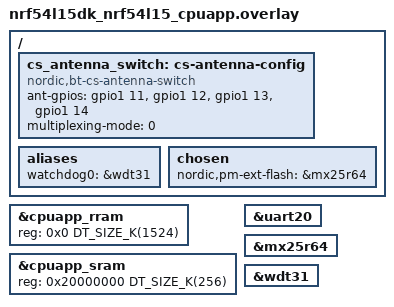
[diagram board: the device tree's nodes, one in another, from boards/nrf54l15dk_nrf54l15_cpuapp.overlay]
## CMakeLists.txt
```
#
# Copyright (c) 2021 Nordic Semiconductor ASA
#
# SPDX-License-Identifier: LicenseRef-Nordic-5-Clause
#

cmake_minimum_required(VERSION 3.20.0)

find_package(Zephyr HINTS $ENV{ZEPHYR_BASE})

project(matter-occupancy-sensor)

# Enable GNU STD support.
include(${ZEPHYR_CONNECTEDHOMEIP_MODULE_DIR}/config/nrfconnect/app/enable-gnu-std.cmake)

# NORDIC SDK APP START

# Include all source files that are located in the Matter common directory.
include(${ZEPHYR_NRF_MODULE_DIR}/samples/matter/common/cmake/source_common.cmake)

# Include Data Model utils
include(${ZEPHYR_NRF_MODULE_DIR}/samples/matter/common/cmake/data_model.cmake)

include(${ZEPHYR_NRF_MODULE_DIR}/samples/matter/common/cmake/zap_helpers.cmake)
ncs_get_zap_parent_dir(ZAP_PARENT_DIR)

target_include_directories(app PRIVATE
    src
    ${ZAP_PARENT_DIR}
)

target_sources(app PRIVATE
    src/app_task.cpp
    src/main.cpp
    src/zcl_callbacks.cpp
    src/occupancy_sensor_base.cpp
    src/occupancy_sensor_pir.cpp
    src/occupancy_sensor_rfs.cpp
    src/channel_sounding_ras_initiator.c
)

target_sources_ifdef(CONFIG_PIR_SUPPORT
	app
	PRIVATE
	src/occupancy_sensor_pir.cpp
)

ncs_configure_data_model()
# NORDIC SDK APP END
```

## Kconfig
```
#
# Copyright (c) 2022 Nordic Semiconductor
#
# SPDX-License-Identifier: LicenseRef-Nordic-5-Clause
#
mainmenu "Matter nRF Connect Occupancy Sensor Example Application"

config PIR_SUPPORT
	bool "PIR sensor support"
	help
	  Enable this option to include Passive Infrared (PIR) sensor support
	  for occupancy detection.

config SIMULATED_PIR_SENSOR
	bool "Simulated PIR sensor with button"
	depends on PIR_SUPPORT
	help
	  Enable this option to simulate PIR sensor input using a button.

config HOLD_TIME_LIMIT_MIN_SEC
	int "Occupancy sensor hold time limit (min)"
	default 1
	range 1 600
	help
	  Minimum time in seconds that the occupancy state remains "occupied"
	  after motion is detected.

config HOLD_TIME_LIMIT_MAX_SEC
	int "Occupancy sensor hold time limit (max)"
	default 600
	range 1 600
	help
	  Maximum time in seconds that the occupancy state remains "occupied"
	  after motion is detected.

config HOLD_TIME_LIMIT_DEFAULT_SEC
	int "Occupancy sensor hold time limit (default)"
	default 10
	range HOLD_TIME_LIMIT_MIN_SEC HOLD_TIME_LIMIT_MAX_SEC
	help
	  Default time in seconds that the occupancy state remains "occupied"
	  after motion is detected.

config HOLD_TIME_LIMIT_RFS_SEC
	int "RF Sensing occupancy hold time limit"
	default 30
	range HOLD_TIME_LIMIT_MIN_SEC HOLD_TIME_LIMIT_MAX_SEC
	help
	  Default time in seconds that the occupancy state remains "occupied"
	  after motion is detected using RF Sensing.

config HOLD_TIME_LIMIT_PIR_SEC
	int "PIR sensor occupancy hold time limit"
	default 10
	range HOLD_TIME_LIMIT_MIN_SEC HOLD_TIME_LIMIT_MAX_SEC
	help
	  Default time in seconds that the occupancy state remains "occupied"
	  after motion is detected using PIR sensor.

config RFS_ACTIVATED_BY_PIR
	bool "RF Sensing activated by PIR sensor"
	depends on PIR_SUPPORT
	help
	  Enable this option to activate RF Sensing only when the PIR sensor
	  detects motion.

config RFS_SENSING_ACTIVE_INTERVAL_MS
	int "RF Sensing active interval"
	default 4000
	range 1000 60000
	help
	  Time interval (in milliseconds) for which RF Sensing remains active
	  before going to sleep (if RFS_ACTIVATED_BY_PIR is enabled, this
	  interval starts after PIR sensor detects motion).

config RFS_SENSING_NORMAL_INACTIVE_INTERVAL_MS
	int "RF Sensing inactive interval in normal mode"
	default 3000
	range 1000 60000
	help
	  Time interval (in milliseconds) in normal mode for which RF Sensing
	  remains inactive.

config RFS_SENSING_LOW_POWER_INACTIVE_INTERVAL_MS
	int "RF Sensing inactive interval in low power mode"
	default 30000
	range 1000 60000
	help
	  Time interval (in milliseconds) in low power mode for which RF Sensing
	  remains inactive.

config RFS_FILTER_RSSI_THRESHOLD
	int "RF Sensing filter RSSI threshold"
	default -80
	range -127 -70
	help
	  RSSI threshold (in dBm) for filtering out weak RF signals.

config RFS_OCCUPANCY_THRESHOLD
	int "RF Sensing occupancy threshold"
	default 5
	range 2 10
	help
	  Range of valid RF signals required to determine occupancy in meter.

# Sample configuration used for Thread networking
if OPENTHREAD

choice OPENTHREAD_NORDIC_LIBRARY_CONFIGURATION
	default OPENTHREAD_NORDIC_LIBRARY_MTD
endchoice

choice OPENTHREAD_DEVICE_TYPE
	default OPENTHREAD_MTD
endchoice

config CHIP_ENABLE_ICD_SUPPORT
	default y

# Reduce Thread TX output power to 0 dBm for SED device
config OPENTHREAD_DEFAULT_TX_POWER
	int
	default 0

endif # OPENTHREAD

source "${ZEPHYR_CONNECTEDHOMEIP_MODULE_DIR}/config/nrfconnect/chip-module/Kconfig.features"
source "${ZEPHYR_CONNECTEDHOMEIP_MODULE_DIR}/config/nrfconnect/chip-module/Kconfig.defaults"
source "${ZEPHYR_NRF_MODULE_DIR}/samples/matter/common/src/Kconfig"
source "Kconfig.zephyr"
```

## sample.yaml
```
sample:
  description: Matter Occupancy Sensor sample
  name: Matter Occupancy Sensor
common:
  tags:
    - sysbuild
    - ci_samples_matter
tests:
  sample.matter.occupancy_sensor.debug:
    sysbuild: true
    build_only: true
    extra_args:
      - CONFIG_NCS_SAMPLE_MATTER_OPERATIONAL_KEYS_MIGRATION_TO_ITS=y
    integration_platforms:
      - nrf52840dk/nrf52840
      - nrf5340dk/nrf5340/cpuapp
      - nrf7002dk/nrf5340/cpuapp
      - nrf54l15dk/nrf54l15/cpuapp
      - nrf54l15dk/nrf54l15/cpuapp/ns
      - nrf54l15dk/nrf54l10/cpuapp
      - nrf54lm20dk/nrf54lm20a/cpuapp
    platform_allow:
      - nrf52840dk/nrf52840
      - nrf5340dk/nrf5340/cpuapp
      - nrf7002dk/nrf5340/cpuapp
      - nrf54l15dk/nrf54l15/cpuapp
      - nrf54l15dk/nrf54l15/cpuapp/ns
      - nrf54l15dk/nrf54l10/cpuapp
      - nrf54lm20dk/nrf54lm20a/cpuapp
  sample.matter.occupancy_sensor.release:
    sysbuild: true
    build_only: true
    extra_args:
      - FILE_SUFFIX=release
      - CONFIG_NCS_SAMPLE_MATTER_OPERATIONAL_KEYS_MIGRATION_TO_ITS=y
    integration_platforms:
      - nrf52840dk/nrf52840
      - nrf5340dk/nrf5340/cpuapp
      - nrf7002dk/nrf5340/cpuapp
      - nrf54l15dk/nrf54l15/cpuapp
      - nrf54l15dk/nrf54l15/cpuapp/ns
      - nrf54l15dk/nrf54l10/cpuapp
      - nrf54lm20dk/nrf54lm20a/cpuapp
    platform_allow:
      - nrf52840dk/nrf52840
      - nrf5340dk/nrf5340/cpuapp
      - nrf7002dk/nrf5340/cpuapp
      - nrf54l15dk/nrf54l15/cpuapp
      - nrf54l15dk/nrf54l15/cpuapp/ns
      - nrf54l15dk/nrf54l10/cpuapp
      - nrf54lm20dk/nrf54lm20a/cpuapp
  sample.matter.occupancy_sensor.smp_dfu:
    sysbuild: true
    build_only: true
    extra_args:
      - CONFIG_CHIP_DFU_OVER_BT_SMP=y
      - CONFIG_NCS_SAMPLE_MATTER_OPERATIONAL_KEYS_MIGRATION_TO_ITS=y
    integration_platforms:
      - nrf52840dk/nrf52840
      - nrf5340dk/nrf5340/cpuapp
      - nrf7002dk/nrf5340/cpuapp
      - nrf54l15dk/nrf54l15/cpuapp
      - nrf54l15dk/nrf54l15/cpuapp/ns
      - nrf54l15dk/nrf54l10/cpuapp
      - nrf54lm20dk/nrf54lm20a/cpuapp
    platform_allow:
      - nrf52840dk/nrf52840
      - nrf5340dk/nrf5340/cpuapp
      - nrf7002dk/nrf5340/cpuapp
      - nrf54l15dk/nrf54l15/cpuapp
      - nrf54l15dk/nrf54l15/cpuapp/ns
      - nrf54l15dk/nrf54l10/cpuapp
      - nrf54lm20dk/nrf54lm20a/cpuapp
  sample.matter.occupancy_sensor.release.internal:
    sysbuild: true
    build_only: true
    extra_args:
      - FILE_SUFFIX=internal
      - occupancy_sensor_EXTRA_CONF_FILE=prj_release.conf
    integration_platforms:
      - nrf54l15dk/nrf54l15/cpuapp
      - nrf54lm20dk/nrf54lm20a/cpuapp
    platform_allow:
      - nrf54l15dk/nrf54l15/cpuapp
      - nrf54lm20dk/nrf54lm20a/cpuapp
  sample.matter.occupancy_sensor.release.internal.smp_dfu:
    sysbuild: true
    build_only: true
    extra_args:
      - FILE_SUFFIX=internal
      - CONFIG_CHIP_DFU_OVER_BT_SMP=y
      - occupancy_sensor_EXTRA_CONF_FILE=prj_release.conf
    integration_platforms:
      - nrf54l15dk/nrf54l15/cpuapp
      - nrf54lm20dk/nrf54lm20a/cpuapp
    platform_allow:
      - nrf54l15dk/nrf54l15/cpuapp
      - nrf54lm20dk/nrf54lm20a/cpuapp
  sample.matter.occupancy_sensor.cc3xx_backend:
    sysbuild: true
    build_only: true
    extra_args:
      - CONFIG_PSA_CRYPTO_DRIVER_CC3XX=y
    integration_platforms:
      - nrf52840dk/nrf52840
      - nrf5340dk/nrf5340/cpuapp
    platform_allow:
      - nrf52840dk/nrf52840
      - nrf5340dk/nrf5340/cpuapp
  sample.matter.occupancy_sensor.smp_dfu.old_ec:
    sysbuild: true
    build_only: true
    extra_args:
      - CONFIG_CHIP_DFU_OVER_BT_SMP=y
      - SB_CONFIG_BOOT_SIGNATURE_TYPE_RSA=y
      - CONFIG_SETTINGS_ZMS_LEGACY=y
    integration_platforms:
      - nrf54l15dk/nrf54l15/cpuapp
    platform_allow:
      - nrf54l15dk/nrf54l15/cpuapp
  sample.matter.occupancy_sensor.certification:
    sysbuild: true
    build_only: true
    extra_args:
      - CONFIG_NCS_SAMPLE_MATTER_CERTIFICATION=y
      - OVERLAY_CONFIG="../common/src/certification/thread_platform/overlay-thread_platform.conf"
      - occupancy_sensor_SNIPPET="diagnostic-logs;matter-debug"
    integration_platforms:
      - nrf52840dk/nrf52840
      - nrf5340dk/nrf5340/cpuapp
      - nrf54l15dk/nrf54l15/cpuapp
      - nrf54lm20dk/nrf54lm20a/cpuapp
    platform_allow:
      - nrf52840dk/nrf52840
      - nrf5340dk/nrf5340/cpuapp
      - nrf54l15dk/nrf54l15/cpuapp
      - nrf54lm20dk/nrf54lm20a/cpuapp
```

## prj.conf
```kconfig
#
# Copyright (c) 2021 Nordic Semiconductor ASA
#
# SPDX-License-Identifier: LicenseRef-Nordic-5-Clause
#

# This sample uses Kconfig.defaults to set options common for all
# samples. This file should contain only options specific for this sample
# or overrides of default values.

# Enable CHIP
CONFIG_CHIP=y
CONFIG_CHIP_PROJECT_CONFIG="src/chip_project_config.h"

# Configure ZAP file name
CONFIG_NCS_SAMPLE_MATTER_ZAP_FILE_PATH="${APPLICATION_CONFIG_DIR}/src/default_zap/occupancy_sensor.zap"

# 32768 == 0x8000 (example Product ID added temporaly,
# but it must be changed with proper PID from the list:
# https://github.com/project-chip/connectedhomeip/blob/482e6fd03196a6de45465a90003947ef4b86e0b1/docs/examples/discussion/PID_allocation_for_example_apps.md)
CONFIG_CHIP_DEVICE_PRODUCT_ID=32768
CONFIG_STD_CPP17=y

# Disable Matter pairing automatically on application start.
CONFIG_CHIP_ENABLE_PAIRING_AUTOSTART=n

# Enable Matter extended announcement and increase duration to 1 hour.
CONFIG_CHIP_BLE_EXT_ADVERTISING=y
CONFIG_CHIP_BLE_ADVERTISING_DURATION=60

# Add support for LEDs and buttons on Nordic development kits
CONFIG_DK_LIBRARY=y

# Bluetooth Low Energy configuration
CONFIG_BT_DEVICE_NAME="M-Occupancy"

# Other settings
CONFIG_THREAD_NAME=y
CONFIG_MPU_STACK_GUARD=y
CONFIG_RESET_ON_FATAL_ERROR=n
CONFIG_CHIP_LIB_SHELL=y
CONFIG_NCS_SAMPLE_MATTER_TEST_SHELL=y

# Disable NFC onboarding
CONFIG_CHIP_NFC_ONBOARDING_PAYLOAD=n

# Reduce application size
CONFIG_USE_SEGGER_RTT=n

# Enable Factory Data feature
CONFIG_CHIP_FACTORY_DATA=y
CONFIG_CHIP_FACTORY_DATA_BUILD=y

CONFIG_NCS_SAMPLES_DEFAULTS=y

CONFIG_BT=y
CONFIG_BT_SMP=y
CONFIG_BT_CENTRAL=y
CONFIG_BT_MAX_CONN=1
CONFIG_BT_BONDABLE=y
CONFIG_BT_SETTINGS=y
CONFIG_BT_ID_MAX=2
CONFIG_BT_MAX_PAIRED=2

CONFIG_BT_GATT_CLIENT=y
CONFIG_BT_GATT_DYNAMIC_DB=y

CONFIG_BT_CHANNEL_SOUNDING=y
CONFIG_BT_RAS=y
CONFIG_BT_RAS_RREQ=y

CONFIG_BT_SCAN=y
CONFIG_BT_SCAN_FILTER_ENABLE=y
CONFIG_BT_SCAN_UUID_CNT=1
CONFIG_BT_SCAN_ADDRESS_CNT=2

# The Ranging Profile recommends a MTU of at least 247 octets.
CONFIG_BT_L2CAP_TX_MTU=498
CONFIG_BT_BUF_ACL_TX_SIZE=502
CONFIG_BT_BUF_ACL_RX_SIZE=502
CONFIG_BT_ATT_PREPARE_COUNT=3
CONFIG_BT_CTLR_DATA_LENGTH_MAX=251

# This reduces RAM usage. Additional RAM is needed to support optional
# features such as mode 3 or multiantenna. Change or remove these if
# using those features
CONFIG_BT_RAS_MODE_3_SUPPORTED=n
CONFIG_BT_RAS_MAX_ANTENNA_PATHS=1
CONFIG_BT_CTLR_SDC_CS_MAX_ANTENNA_PATHS=1
CONFIG_BT_CTLR_SDC_CS_NUM_ANTENNAS=1
CONFIG_BT_CTLR_SDC_CS_STEP_MODE3=n
CONFIG_BT_CTLR_SDC_CS_ROLE_INITIATOR_ONLY=y

# Disabling the CS Test command reduces flash usage
CONFIG_BT_CTLR_CHANNEL_SOUNDING_TEST=n

# This allows CS and ACL to use different PHYs
CONFIG_BT_TRANSMIT_POWER_CONTROL=y

# This improves the performance of floating-point operations
CONFIG_FPU=y
CONFIG_FPU_SHARING=y
CONFIG_CBPRINTF_FP_SUPPORT=y

CONFIG_BT_CS_DE=y
CONFIG_BT_CS_DE_512_NFFT=y
CONFIG_BT_RX_STACK_SIZE=5120

# 2M PHY is disabled in Matter platform for nRF Connect SDK by default.
# Enable it here to allow using 2M PHY for Bluetooth Channel Sounding.
CONFIG_BT_CTLR_PHY_2M=y

CONFIG_CHIP_ICD_SLOW_POLL_INTERVAL=15000
CONFIG_CHIP_APP_LOG_LEVEL=3
```

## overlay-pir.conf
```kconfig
CONFIG_PIR_SUPPORT=y
CONFIG_NCS_SAMPLE_MATTER_ZAP_FILE_PATH="${APPLICATION_CONFIG_DIR}/src/pir/occupancy_sensor.zap"
```

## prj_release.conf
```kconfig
#
# Copyright (c) 2021 Nordic Semiconductor ASA
#
# SPDX-License-Identifier: LicenseRef-Nordic-5-Clause
#

# This sample uses Kconfig.defaults to set options common for all
# samples. This file should contain only options specific for this sample
# or overrides of default values.

# Enable CHIP
CONFIG_CHIP=y
CONFIG_CHIP_PROJECT_CONFIG="src/chip_project_config.h"

# Configure ZAP file name
CONFIG_NCS_SAMPLE_MATTER_ZAP_FILE_PATH="${APPLICATION_CONFIG_DIR}/src/default_zap/occupancy_sensor.zap"

# 32768 == 0x8000 (example Product ID added temporaly,
# but it must be changed with proper PID from the list:
# https://github.com/project-chip/connectedhomeip/blob/482e6fd03196a6de45465a90003947ef4b86e0b1/docs/examples/discussion/PID_allocation_for_example_apps.md)
CONFIG_CHIP_DEVICE_PRODUCT_ID=32768
CONFIG_STD_CPP17=y

# Disable Matter pairing automatically on application start.
CONFIG_CHIP_ENABLE_PAIRING_AUTOSTART=n

# Enable Matter extended announcement and increase duration to 1 hour.
CONFIG_CHIP_BLE_EXT_ADVERTISING=y
CONFIG_CHIP_BLE_ADVERTISING_DURATION=60

# Add support for LEDs and buttons on Nordic development kits
CONFIG_DK_LIBRARY=y

# Bluetooth Low Energy configuration
CONFIG_BT_DEVICE_NAME="M-Occupancy"

# Suspend devices when the CPU goes into sleep
CONFIG_PM_DEVICE=y

# Enable system reset on fatal error
CONFIG_RESET_ON_FATAL_ERROR=y

# Try to disable unused RAM blocks to reduce power consumption
CONFIG_RAM_POWER_DOWN_LIBRARY=y

# Disable all debug features
CONFIG_USE_SEGGER_RTT=n
CONFIG_SHELL=n
CONFIG_OPENTHREAD_SHELL=n
CONFIG_CHIP_LIB_SHELL=n
CONFIG_CONSOLE=n
CONFIG_UART_CONSOLE=n
CONFIG_SERIAL=n
CONFIG_LOG=n
CONFIG_LOG_MODE_MINIMAL=n
CONFIG_ASSERT_VERBOSE=n
CONFIG_ASSERT_NO_FILE_INFO=y
CONFIG_PRINTK=n
CONFIG_PRINTK_SYNC=n
CONFIG_THREAD_NAME=n
CONFIG_BOOT_BANNER=n

# Disable NFC onboarding
CONFIG_CHIP_NFC_ONBOARDING_PAYLOAD=n

# Enable Factory Data feature
CONFIG_CHIP_FACTORY_DATA=y
CONFIG_CHIP_FACTORY_DATA_BUILD=y

# Enable Watchdog
CONFIG_NCS_SAMPLE_MATTER_WATCHDOG=y

CONFIG_NCS_SAMPLES_DEFAULTS=y

CONFIG_BT=y
CONFIG_BT_SMP=y
CONFIG_BT_CENTRAL=y
CONFIG_BT_MAX_CONN=1
CONFIG_BT_BONDABLE=y
CONFIG_BT_SETTINGS=y
CONFIG_BT_ID_MAX=2
CONFIG_BT_MAX_PAIRED=2

CONFIG_BT_GATT_CLIENT=y
CONFIG_BT_GATT_DYNAMIC_DB=y

CONFIG_BT_CHANNEL_SOUNDING=y
CONFIG_BT_RAS=y
CONFIG_BT_RAS_RREQ=y

CONFIG_BT_SCAN=y
CONFIG_BT_SCAN_FILTER_ENABLE=y
CONFIG_BT_SCAN_UUID_CNT=1
CONFIG_BT_SCAN_ADDRESS_CNT=2

# The Ranging Profile recommends a MTU of at least 247 octets.
CONFIG_BT_L2CAP_TX_MTU=498
CONFIG_BT_BUF_ACL_TX_SIZE=502
CONFIG_BT_BUF_ACL_RX_SIZE=502
CONFIG_BT_ATT_PREPARE_COUNT=3
CONFIG_BT_CTLR_DATA_LENGTH_MAX=251

# This reduces RAM usage. Additional RAM is needed to support optional
# features such as mode 3 or multiantenna. Change or remove these if
# using those features
CONFIG_BT_RAS_MODE_3_SUPPORTED=n
CONFIG_BT_RAS_MAX_ANTENNA_PATHS=1
CONFIG_BT_CTLR_SDC_CS_MAX_ANTENNA_PATHS=1
CONFIG_BT_CTLR_SDC_CS_NUM_ANTENNAS=1
CONFIG_BT_CTLR_SDC_CS_STEP_MODE3=n
CONFIG_BT_CTLR_SDC_CS_ROLE_INITIATOR_ONLY=y

# Disabling the CS Test command reduces flash usage
CONFIG_BT_CTLR_CHANNEL_SOUNDING_TEST=n

# This allows CS and ACL to use different PHYs
CONFIG_BT_TRANSMIT_POWER_CONTROL=y

# This improves the performance of floating-point operations
CONFIG_FPU=y
CONFIG_FPU_SHARING=y
CONFIG_CBPRINTF_FP_SUPPORT=y

CONFIG_BT_CS_DE=y
CONFIG_BT_CS_DE_512_NFFT=y
CONFIG_BT_RX_STACK_SIZE=5120

# 2M PHY is disabled in Matter platform for nRF Connect SDK by default.
# Enable it here to allow using 2M PHY for Bluetooth Channel Sounding.
CONFIG_BT_CTLR_PHY_2M=y

CONFIG_CHIP_ICD_SLOW_POLL_INTERVAL=15000
```

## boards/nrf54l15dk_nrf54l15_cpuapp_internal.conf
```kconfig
#
# Copyright (c) 2024 Nordic Semiconductor ASA
#
# SPDX-License-Identifier: LicenseRef-Nordic-5-Clause
#

# Disable SPI
CONFIG_CHIP_SPI_NOR=n

# Enable Watchdog
CONFIG_NCS_SAMPLE_MATTER_WATCHDOG=y
```

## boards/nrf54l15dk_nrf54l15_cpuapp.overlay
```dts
/*
 * Copyright (c) 2024 Nordic Semiconductor ASA
 *
 * SPDX-License-Identifier: LicenseRef-Nordic-5-Clause
 */

/ {
	cs_antenna_switch: cs-antenna-config {
		status = "okay";
		compatible = "nordic,bt-cs-antenna-switch";
		ant-gpios = <&gpio1 11 (GPIO_ACTIVE_HIGH)>,
			    <&gpio1 12 (GPIO_ACTIVE_HIGH)>,
			    <&gpio1 13 (GPIO_ACTIVE_HIGH)>,
			    <&gpio1 14 (GPIO_ACTIVE_HIGH)>;
		multiplexing-mode = <0>;
	};
};

/ {
	aliases {
		// Use watchdog wdt31 as the application watchdog
		watchdog0 = &wdt31;
	};

	chosen {
		nordic,pm-ext-flash = &mx25r64;
	};
};

// restore full RRAM and SRAM space - by default some parts are dedicated to FLRP
&cpuapp_rram {
	reg = <0x0 DT_SIZE_K(1524)>;
};

&cpuapp_sram {
	reg = <0x20000000 DT_SIZE_K(256)>;
	ranges = <0x0 0x20000000  0x40000>;
};

// TODO: re-enable HWFC once it's fixed
&uart20 {
	/delete-property/ hw-flow-control;
};

&mx25r64 {
	status = "okay";
};

&wdt31 {
	status = "okay";
};
```

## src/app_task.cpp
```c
/*
 * Copyright (c) 2021 Nordic Semiconductor ASA
 *
 * SPDX-License-Identifier: LicenseRef-Nordic-5-Clause
 */

#include "app_task.h"

#include "app/matter_init.h"
#include "app/task_executor.h"
#include "board/board.h"
#include "lib/core/CHIPError.h"
#include "lib/support/CodeUtils.h"
#include "channel_sounding_ras_initiator.h"

#include <setup_payload/OnboardingCodesUtil.h>

#include <zephyr/logging/log.h>

LOG_MODULE_DECLARE(app, CONFIG_CHIP_APP_LOG_LEVEL);

using namespace ::chip;
using namespace ::chip::app;
using namespace ::chip::DeviceLayer;

#define MODE_BUTTON_MASK DK_BTN2_MSK

void AppTask::ButtonEventHandler(Nrf::ButtonState state, Nrf::ButtonMask hasChanged)
{
	if (MODE_BUTTON_MASK & hasChanged) {
		bool button_pressed = (MODE_BUTTON_MASK & state) != 0;
		Nrf::PostTask([button_pressed] { 
			OccupancySensorRFS::Instance().HandleButtonEvent(button_pressed);
		});
	}
}

void AppTask::MatterEventHandler(const ChipDeviceEvent *event, intptr_t /* unused */)
{
	switch (event->Type) {
		case DeviceEventType::kThreadStateChange:
			if(ConnectivityMgrImpl().IsIPv6NetworkProvisioned() &&
						ConnectivityMgrImpl().IsIPv6NetworkEnabled()) {
				LOG_INF("Thread is provisioned and enabled");
#if !defined(CONFIG_RFS_ACTIVATED_BY_PIR)
				LOG_INF("Enabling Channel Sounding procedure");
				channel_sounding_procedure_enable(true);
#endif
			} else {
				LOG_INF("Thread is not ready");
#if !defined(CONFIG_RFS_ACTIVATED_BY_PIR)
				LOG_INF("Disabling Channel Sounding procedure");
				channel_sounding_procedure_enable(false);
#endif	
			}
			break;
	default:
		break;
	}
}

CHIP_ERROR AppTask::Init()
{
	/* Initialize Matter stack */
	ReturnErrorOnFailure(Nrf::Matter::PrepareServer());

	if (!Nrf::GetBoard().Init(ButtonEventHandler)) {
		LOG_ERR("User interface initialization failed.");
		return CHIP_ERROR_INCORRECT_STATE;
	}

	/* Register Matter event handler that controls the connectivity status LED based on the captured Matter network
	 * state. */
	ReturnErrorOnFailure(Nrf::Matter::RegisterEventHandler(Nrf::Board::DefaultMatterEventHandler, 0));
	ReturnErrorOnFailure(Nrf::Matter::RegisterEventHandler(MatterEventHandler, 0));

	/* Initialize RF Sensing occupancy sensor */
	ReturnErrorOnFailure(OccupancySensorRFS::Instance().Init());

#if defined(CONFIG_PIR_SUPPORT)
	/* Initialize PIR occupancy sensor */
	ReturnErrorOnFailure(OccupancySensorPIR::Instance().Init());
#endif

	return Nrf::Matter::StartServer();
}

CHIP_ERROR AppTask::StartApp()
{
	ReturnErrorOnFailure(Init());

	while (true) {
		Nrf::DispatchNextTask();
	}

	return CHIP_NO_ERROR;
}
```

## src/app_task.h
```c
/*
 * Copyright (c) 2021 Nordic Semiconductor ASA
 *
 * SPDX-License-Identifier: LicenseRef-Nordic-5-Clause
 */

#pragma once

#include <platform/CHIPDeviceLayer.h>
#include "occupancy_sensor_pir.h"
#include "occupancy_sensor_rfs.h"

#include "board/led_widget.h"
#include "board/board.h"

struct k_timer;

class AppTask {
public:
	static AppTask &Instance()
	{
		static AppTask sAppTask;
		return sAppTask;
	};

	CHIP_ERROR StartApp();

private:
	CHIP_ERROR Init();
	static void ButtonEventHandler(Nrf::ButtonState state, Nrf::ButtonMask hasChanged);
	static void MatterEventHandler(const chip::DeviceLayer::ChipDeviceEvent *event, intptr_t data);
};
```

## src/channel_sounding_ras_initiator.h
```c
/*
 * Copyright (c) 2024 Nordic Semiconductor ASA
 *
 * SPDX-License-Identifier: LicenseRef-Nordic-5-Clause
 */

#pragma once

#include <zephyr/bluetooth/conn.h>

#ifdef __cplusplus
extern "C" {
#endif

/**
 * @brief Enum representing the Channel Sounding state
 */
enum channel_sounding_state {
    CS_STATE_UNINITIALIZED = -1,
    CS_STATE_STOPPED,
    CS_STATE_CONNECTING,
    CS_STATE_STARTED
};

typedef void (*channel_sounding_event_handler_t)(uint8_t index, float distance);

/**
 * @brief Initialize the Channel Sounding RAS Initiator module
 * 
 * This function initializes the Channel Sounding functionality and starts
 * the dedicated thread that manages the Channel Sounding operations.
 * 
 * @param event_handler Callback function to handle Channel Sounding events
 * 
 * @return 0 on success, negative error code on failure
 */
int channel_sounding_init(channel_sounding_event_handler_t event_handler);

/**
 * @brief Get the current Channel Sounding state
 * 
 * @return channel_sounding_state enum value representing the current state
 */
enum channel_sounding_state get_channel_sounding_state(void);

/**
 * @brief Enable or disable Channel Sounding procedures
 * 
 * This function provides a wrapper around bt_le_cs_procedure_enable to
 * allow other modules to control Channel Sounding functionality.
 * 
 * @param enable true to enable Channel Sounding, false to disable
 * @return 0 on success, negative error code on failure
 */
int channel_sounding_procedure_enable(bool enable);

/**
 * @brief Set the inactive interval between Channel Sounding procedures
 * 
 * This function sets the time interval (in milliseconds) between
 * consecutive Channel Sounding procedures when they are enabled.
 * 
 * @param interval_ms Inactive interval in milliseconds
 * @return 0 on success, negative error code on failure
 */
int channel_sounding_set_inactive_interval(uint32_t interval_ms);

/**
 * @brief Enable or disable preemptive mode for Channel Sounding
 * 
 * In preemptive mode, Channel Sounding procedures reconnect to
 * last known devices with higher priority. In non-preemptive mode,
 * devices are scanned and connected in the order they were last paired.
 * 
 * @param enable true to enable preemptive mode, false to disable
 * @return 0 on success, negative error code on failure
 */
int channel_sounding_set_preemptive_mode(bool enable);

/**
 * @brief Check if Channel Sounding is in preemptive mode
 * 
 * @return true if preemptive mode is enabled, false otherwise
 */
bool channel_sounding_is_preemptive_mode();

#ifdef __cplusplus
}
#endif
```

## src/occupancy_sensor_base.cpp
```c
/*
 * Copyright (c) 2024 Nordic Semiconductor ASA
 *
 * SPDX-License-Identifier: LicenseRef-Nordic-5-Clause
 */

#include "occupancy_sensor_base.h"
#include "app/task_executor.h"

#include <app/server/Server.h>
#include <app/util/attribute-storage.h>
#include <app/clusters/occupancy-sensor-server/occupancy-sensor-server.h>
#include <app/EventLogging.h>
#include <app-common/zap-generated/attributes/Accessors.h>
#include <platform/CHIPDeviceLayer.h>
#include <zephyr/logging/log.h>

LOG_MODULE_DECLARE(app, CONFIG_CHIP_APP_LOG_LEVEL);

using namespace chip;
using namespace chip::app;
using namespace chip::app::Clusters;
using namespace chip::app::Clusters::OccupancySensing;
using namespace chip::app::Clusters::OccupancySensing::Structs;
using namespace chip::DeviceLayer;

CHIP_ERROR OccupancySensorBase::SetOccupancyState(bool occupied, chip::EndpointId endpointId)
{
    if (!mInitialized) {
        LOG_ERR("Occupancy sensor not initialized");
        return CHIP_ERROR_INCORRECT_STATE;
    }

    if (endpointId == kInvalidEndpointId) {
        LOG_ERR("Invalid endpoint ID");
        return CHIP_ERROR_INVALID_ARGUMENT;
    }

    if (occupied)
    {
        uint16_t * holdTime = chip::app::Clusters::OccupancySensing::GetHoldTimeForEndpoint(endpointId);
        if (holdTime != nullptr)
        {
            CHIP_ERROR err = chip::DeviceLayer::SystemLayer().StartTimer(
                chip::System::Clock::Seconds16(*holdTime), OccupancySensorBase::OccupancyPresentTimerHandler,
                reinterpret_cast<void *>(static_cast<uintptr_t>(endpointId)));
            LOG_DBG("Start HoldTime timer");
            if (CHIP_NO_ERROR != err)
            {
                LOG_ERR("Failed to start HoldTime timer.");
            }
        }
    }

    chip::BitMask<Clusters::OccupancySensing::OccupancyBitmap> currentOccupancy;
    Protocols::InteractionModel::Status status = OccupancySensing::Attributes::Occupancy::Get(endpointId, &currentOccupancy);
    VerifyOrDie(status == Protocols::InteractionModel::Status::Success);

    if (static_cast<BitMask<chip::app::Clusters::OccupancySensing::OccupancyBitmap>>(occupied) == currentOccupancy) {
        // No state change needed
        return CHIP_NO_ERROR;
    }

    LOG_INF("Occupancy sensor state change: %s -> %s", 
            currentOccupancy.Has(Clusters::OccupancySensing::OccupancyBitmap::kOccupied) ? "OCCUPIED" : "UNOCCUPIED",
            occupied ? "OCCUPIED" : "UNOCCUPIED");

    status = chip::app::Clusters::OccupancySensing::Attributes::Occupancy::Set(
        endpointId, (uint8_t)occupied);
    if (status != Protocols::InteractionModel::Status::Success)
    {
        LOG_ERR("Failed to set occupancy attribute: %d", static_cast<int>(status));
        return CHIP_ERROR_INTERNAL;
    }

    // Send OccupancyChanged event
    chip::app::Clusters::OccupancySensing::Events::OccupancyChanged::Type event;
    event.occupancy = occupied ? chip::app::Clusters::OccupancySensing::OccupancyBitmap::kOccupied : static_cast<chip::app::Clusters::OccupancySensing::OccupancyBitmap>(0);

    EventNumber eventNumber;
    CHIP_ERROR err = LogEvent(event, endpointId, eventNumber);
    if (err != CHIP_NO_ERROR) {
        LOG_ERR("Failed to log occupancy event: %" CHIP_ERROR_FORMAT, err.Format());
    } else {
        LOG_INF("OccupancyChanged event sent (EventNumber: %" PRIu64 ")", eventNumber);
    }

    return CHIP_NO_ERROR;
}

bool OccupancySensorBase::IsOccupied(chip::EndpointId endpointId)
{
    if (endpointId == kInvalidEndpointId) {
        LOG_ERR("Invalid endpoint ID");
        return false;
    }
    chip::BitMask<Clusters::OccupancySensing::OccupancyBitmap> currentOccupancy;
    Protocols::InteractionModel::Status status = OccupancySensing::Attributes::Occupancy::Get(endpointId, &currentOccupancy);
    VerifyOrDie(status == Protocols::InteractionModel::Status::Success);
    return currentOccupancy.Has(Clusters::OccupancySensing::OccupancyBitmap::kOccupied);
}

void OccupancySensorBase::OccupancyPresentTimerHandler(System::Layer * systemLayer, void * appState)
{
    EndpointId endpointId = static_cast<EndpointId>(reinterpret_cast<uintptr_t>(appState));
    chip::BitMask<Clusters::OccupancySensing::OccupancyBitmap> currentOccupancy;

    Protocols::InteractionModel::Status status = OccupancySensing::Attributes::Occupancy::Get(endpointId, &currentOccupancy);
    VerifyOrDie(status == Protocols::InteractionModel::Status::Success);

    uint8_t clearValue = 0;
    if (!currentOccupancy.Has(Clusters::OccupancySensing::OccupancyBitmap::kOccupied))
    {
        return;
    }

    status = OccupancySensing::Attributes::Occupancy::Set(endpointId, clearValue);
    if (status != Protocols::InteractionModel::Status::Success)
    {
        LOG_ERR("Failed to set occupancy state.");
    }
    else
    {
        LOG_INF("Set Occupancy attribute to clear");
    }

    // Send OccupancyChanged event
    chip::app::Clusters::OccupancySensing::Events::OccupancyChanged::Type event;
    event.occupancy = clearValue ? chip::app::Clusters::OccupancySensing::OccupancyBitmap::kOccupied : static_cast<chip::app::Clusters::OccupancySensing::OccupancyBitmap>(0);

    EventNumber eventNumber;
    CHIP_ERROR err = LogEvent(event, endpointId, eventNumber);
    if (err != CHIP_NO_ERROR) {
        LOG_ERR("Failed to log occupancy event: %" CHIP_ERROR_FORMAT, err.Format());
    } else {
        LOG_INF("OccupancyChanged event sent (EventNumber: %" PRIu64 ")", eventNumber);
    }
    LOG_INF("Occupancy sensor state change: OCCUPIED -> UNOCCUPIED");
}

CHIP_ERROR OccupancySensorBase::InitializeClusterInstance(chip::BitMask<chip::app::Clusters::OccupancySensing::Feature, uint32_t> features)
{
    static std::unique_ptr<OccupancySensing::Instance> occupancySensorInstance;
    occupancySensorInstance = std::make_unique<OccupancySensing::Instance>(features);

    mClusterInstance = occupancySensorInstance.get();
    
    CHIP_ERROR err = mClusterInstance->Init();
    if (err != CHIP_NO_ERROR) {
        LOG_ERR("Failed to initialize OccupancySensing cluster: %" CHIP_ERROR_FORMAT, err.Format());
        return err;
    }

    return CHIP_NO_ERROR;
}
```

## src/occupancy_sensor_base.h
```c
/*
 * Copyright (c) 2024 Nordic Semiconductor ASA
 *
 * SPDX-License-Identifier: LicenseRef-Nordic-5-Clause
 */

#pragma once

#include <platform/CHIPDeviceLayer.h>
#include <app/clusters/occupancy-sensor-server/occupancy-sensor-server.h>
#include <zephyr/kernel.h>

/**
 * @brief Base class for occupancy sensors in Matter
 * 
 * This abstract base class provides common functionality for different
 * types of occupancy sensors (PIR, RF Sensing, etc.) including:
 * - SetOccupancyState() method
 * - IsOccupied() method
 * - IsValidEndpoint() pure virtual method
 * - Common timer handling for occupancy timeout
 * - Matter cluster instance management
 */
class OccupancySensorBase {
public:
    virtual ~OccupancySensorBase() = default;

    /**
     * @brief Initialize the occupancy sensor
     * 
     * Pure virtual method that must be implemented by derived classes
     * to handle sensor-specific initialization
     * 
     * @return CHIP_ERROR CHIP_NO_ERROR on success, error code otherwise
     */
    virtual CHIP_ERROR Init() = 0;

    /**
     * @brief Set the occupancy state
     * 
     * Updates the occupancy attribute and sends OccupancyChanged events
     * Common implementation for all sensor types
     * 
     * @param occupied true if occupied, false if unoccupied
     * @return CHIP_ERROR CHIP_NO_ERROR on success, error code otherwise
     */
    CHIP_ERROR SetOccupancyState(bool occupied, chip::EndpointId endpointId);

    /**
     * @brief Get the current occupancy state
     * 
     * Virtual method that can be overridden by derived classes if they
     * need custom state tracking (default queries Matter attribute directly)
     * 
     * @return true if occupied, false if unoccupied
     */
    virtual bool IsOccupied(chip::EndpointId endpointId);

    /**
     * @brief Validate if the given endpoint ID is valid for this sensor
     * 
     * Pure virtual method that must be implemented by derived classes
     * to specify which endpoints they support
     * 
     * @param endpointId The endpoint ID to validate
     * @return true if valid, false otherwise
     */
    virtual bool IsValidEndpoint(chip::EndpointId endpointId) const = 0;

protected:
    /**
     * @brief Constructor for derived classes
     */
    OccupancySensorBase() = default;

    /**
     * @brief Common timer callback for occupancy timeout
     * 
     * Static method that handles occupancy timeout for all sensor types
     * Called when the occupancy timeout expires to set state to unoccupied
     */
    static void OccupancyPresentTimerHandler(chip::System::Layer * systemLayer, void * appState);

    /**
     * @brief Initialize the Matter OccupancySensing cluster
     * 
     * Common helper method to initialize the cluster instance with specified features
     * 
     * @param features BitMask of OccupancySensing features to enable
     * @return CHIP_ERROR CHIP_NO_ERROR on success, error code otherwise
     */
    CHIP_ERROR InitializeClusterInstance(chip::BitMask<chip::app::Clusters::OccupancySensing::Feature, uint32_t> features);

    // State tracking
    bool mInitialized = false;
    
    // Matter cluster instance
    chip::app::Clusters::OccupancySensing::Instance *mClusterInstance = nullptr;

private:
    // Non-copyable
    OccupancySensorBase(const OccupancySensorBase&) = delete;
    OccupancySensorBase& operator=(const OccupancySensorBase&) = delete;
};
```

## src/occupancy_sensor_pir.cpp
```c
/*
 * Copyright (c) 2024 Nordic Semiconductor ASA
 *
 * SPDX-License-Identifier: LicenseRef-Nordic-5-Clause
 */

#include "occupancy_sensor_pir.h"
#include "app/task_executor.h"

#include <app/server/Server.h>
#include <app/util/attribute-storage.h>
#include <app/clusters/occupancy-sensor-server/occupancy-sensor-server.h>
#include <app/EventLogging.h>
#include <app-common/zap-generated/attributes/Accessors.h>
#include <platform/CHIPDeviceLayer.h>
#include <zephyr/drivers/gpio.h>
#include <zephyr/devicetree.h>
#include <zephyr/logging/log.h>

#include "channel_sounding_ras_initiator.h"

LOG_MODULE_DECLARE(app, CONFIG_CHIP_APP_LOG_LEVEL);

using namespace chip;
using namespace chip::app;
using namespace chip::app::Clusters;
using namespace chip::app::Clusters::OccupancySensing;
using namespace chip::app::Clusters::OccupancySensing::Structs;
using namespace chip::DeviceLayer;

// GPIO device node from device tree
#define PIR_GPIO_NODE DT_NODELABEL(gpio0)

CHIP_ERROR OccupancySensorPIR::Init()
{
    int ret;

    if (mInitialized) {
        LOG_INF("PIR sensor already initialized");
        return CHIP_NO_ERROR;
    }

    LOG_INF("Initializing PIR occupancy sensor on P0.%d for nrf54L15DK", kPirPin);

    // Get GPIO device from device tree
    mGpioDevice = DEVICE_DT_GET(PIR_GPIO_NODE);
    if (!device_is_ready(mGpioDevice)) {
        LOG_ERR("GPIO device not ready");
        return CHIP_ERROR_INTERNAL;
    }

#if defined(CONFIG_SIMULATED_PIR_SENSOR)
    if (gpio_pin_configure(mGpioDevice, kPirPin, GPIO_INPUT | GPIO_PULL_UP) < 0) {
        LOG_ERR("Failed to configure PIR GPIO pin P0.%d", kPirPin);
        return CHIP_ERROR_INTERNAL;
    }
#else
    if (gpio_pin_configure(mGpioDevice, kPirPin, GPIO_INPUT | GPIO_PULL_DOWN) < 0) {
        LOG_ERR("Failed to configure PIR GPIO pin P0.%d", kPirPin);
        return CHIP_ERROR_INTERNAL;
    }
#endif

    // Initialize GPIO callback structure
    gpio_init_callback(&mGpioCallback, PirInterruptCallback, BIT(kPirPin));
    ret = gpio_add_callback(mGpioDevice, &mGpioCallback);
    if (ret < 0) {
        LOG_ERR("Failed to add GPIO callback: %d", ret);
        return CHIP_ERROR_INTERNAL;
    }

    // Enable interrupt on rising edge (PIR sensor activation)
    ret = gpio_pin_interrupt_configure(mGpioDevice, kPirPin, GPIO_INT_EDGE_RISING);
    if (ret < 0) {
        LOG_ERR("Failed to configure GPIO interrupt: %d", ret);
        return CHIP_ERROR_INTERNAL;
    }

    // Initialize work queue and timer for deferred processing
    k_work_init(&mPirWork, PirWorkHandler);

    // Initialize Matter OccupancySensing cluster instance with PIR feature
    CHIP_ERROR err = InitializeClusterInstance(BitMask<OccupancySensing::Feature, uint32_t>(OccupancySensing::Feature::kPassiveInfrared));
    if (err != CHIP_NO_ERROR) {
        return err;
    }

    mInitialized = true;
    LOG_INF("PIR occupancy sensor initialized successfully on Endpoint %d", kPirEndpoint);

    return CHIP_NO_ERROR;
}




void OccupancySensorPIR::PirInterruptCallback(const struct device *dev, struct gpio_callback *cb, uint32_t pins)
{
    ARG_UNUSED(dev);
    ARG_UNUSED(cb);
    ARG_UNUSED(pins);
    
    // Get the sensor instance using singleton pattern
    OccupancySensorPIR *sensor = &OccupancySensorPIR::Instance();
    
    // Schedule work to handle the PIR sensor activation in a different context
    // This is important to avoid doing too much work in the interrupt context
    k_work_submit(&sensor->mPirWork);
}

void OccupancySensorPIR::PirWorkHandler(k_work *work)
{
    ARG_UNUSED(work);

    // Get the sensor instance using singleton pattern
    OccupancySensorPIR *sensor = &OccupancySensorPIR::Instance();
    
    // Read the current GPIO state to confirm the interrupt was valid
    int pinValue = gpio_pin_get(sensor->mGpioDevice, kPirPin);
    LOG_INF("GPIO pin value: %d", pinValue);
    if (pinValue > 0) {
        // PIR sensor detected motion - set occupied state
        Nrf::PostTask([sensor] { 
            CHIP_ERROR err = sensor->SetOccupancyState(true, OccupancySensorPIR::Instance().kPirEndpoint);
            if (err != CHIP_NO_ERROR) {
                LOG_ERR("Failed to set occupied state: %" CHIP_ERROR_FORMAT, err.Format());
            }
        });
    }
}
```

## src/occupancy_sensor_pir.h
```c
/*
 * Copyright (c) 2024 Nordic Semiconductor ASA
 *
 * SPDX-License-Identifier: LicenseRef-Nordic-5-Clause
 */

#pragma once

#include "occupancy_sensor_base.h"
#include <zephyr/drivers/gpio.h>

/**
 * @brief PIR Occupancy Sensor implementation for Matter
 * 
 * This class implements a PIR (Passive Infrared) occupancy sensor for Matter
 * inheriting common functionality from OccupancySensorBase
 */
class OccupancySensorPIR : public OccupancySensorBase {
public:
    /**
     * @brief Get the singleton instance
     */
    static OccupancySensorPIR &Instance()
    {
        static OccupancySensorPIR sInstance;
        return sInstance;
    }

    /**
     * @brief Initialize the PIR occupancy sensor
     * 
     * Sets up GPIO as input with interrupt for PIR sensor detection
     * and initializes the Matter OccupancySensing cluster on Endpoint 1.
     * 
     * @return CHIP_ERROR CHIP_NO_ERROR on success, error code otherwise
     */
    CHIP_ERROR Init() override;

    /**
     * @brief Validate if the given endpoint ID is valid for this sensor
     * 
     * Implementation of pure virtual method from base class
     * 
     * @param endpointId The endpoint ID to validate
     * @return true if valid, false otherwise
     */
    bool IsValidEndpoint(chip::EndpointId endpointId) const override
    {
        return endpointId == kPirEndpoint;
    }

    /**
     * @brief Get the endpoint ID for the occupancy sensor
     * 
     * @return chip::EndpointId The endpoint ID
     */
    chip::EndpointId GetEndpointId() const
    {
        return kPirEndpoint;
    }

private:
    OccupancySensorPIR() = default;
    ~OccupancySensorPIR() = default;

    // Non-copyable
    OccupancySensorPIR(const OccupancySensorPIR&) = delete;
    OccupancySensorPIR& operator=(const OccupancySensorPIR&) = delete;

    /**
     * @brief GPIO interrupt callback for PIR sensor
     * 
     * Called when PIR sensor detects motion (rising edge)
     */
    static void PirInterruptCallback(const struct device *dev, struct gpio_callback *cb, uint32_t pins);

    /**
     * @brief Work handler for PIR sensor state changes
     * 
     * Handles the actual occupancy state update in the system work queue context
     */
    static void PirWorkHandler(k_work *work);


    // Configuration constants
    static constexpr chip::EndpointId kPirEndpoint = 1 + CONFIG_BT_MAX_PAIRED;
#if defined(CONFIG_SIMULATED_PIR_SENSOR)
    static constexpr uint8_t kPirPin = 4; // P0.04 (simulated with button)
#else
    static constexpr uint8_t kPirPin = 3; // P0.03
#endif
    
    // GPIO and Zephyr resources
    const struct device *mGpioDevice = nullptr;
    struct gpio_callback mGpioCallback;
    struct k_work mPirWork;
};
```

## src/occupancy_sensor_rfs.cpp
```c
/*
 * Copyright (c) 2024 Nordic Semiconductor ASA
 *
 * SPDX-License-Identifier: LicenseRef-Nordic-5-Clause
 */

#include "occupancy_sensor_rfs.h"
#include "channel_sounding_ras_initiator.h"
#include "app/task_executor.h"
#include "app/matter_init.h"

#include "lib/support/CodeUtils.h"

#include <app/server/Server.h>
#include <app/util/attribute-storage.h>
#include <app/util/endpoint-config-api.h>
#include <app/clusters/occupancy-sensor-server/occupancy-sensor-server.h>
#include <app/EventLogging.h>
#include <app-common/zap-generated/attributes/Accessors.h>
#include <platform/CHIPDeviceLayer.h>
#include <zephyr/logging/log.h>
#include <dk_buttons_and_leds.h>
#include <math.h>

LOG_MODULE_DECLARE(app, CONFIG_CHIP_APP_LOG_LEVEL);

using namespace chip;
using namespace chip::app;
using namespace chip::app::Clusters;
using namespace chip::app::Clusters::OccupancySensing;
using namespace chip::app::Clusters::OccupancySensing::Structs;
using namespace chip::DeviceLayer;

void OccupancySensorRFS::RfsEventHandler(uint8_t bond_idx, float distance)
{
    LOG_DBG("Channel Sounding event received");

    if (distance < kOccupancyThreshold) {
        LOG_DBG("Distance %.2f below threshold %.1f - setting occupied", (double)distance, (double)kOccupancyThreshold);

        if (bond_idx >=0 && bond_idx < CONFIG_BT_MAX_PAIRED) {
            LOG_DBG("Confirmed connection to known RF sensing device");
            OccupancySensorRFS::Instance().remote_address_valid = true;
            // Map bond index to endpoint ID, skip endpoint 0 (root endpoint)
            OccupancySensorRFS::Instance().mConnectedDevice = bond_idx + 1;
        } else {
            OccupancySensorRFS::Instance().remote_address_valid = false;
            LOG_ERR("Failed to get remote device address");
            return;
        }

        Nrf::PostTask([] {
            CHIP_ERROR err = OccupancySensorRFS::Instance().SetOccupancyState(true, OccupancySensorRFS::Instance().mConnectedDevice);
            if (err != CHIP_NO_ERROR) {
                LOG_ERR("Failed to set RF Sensing occupancy state: %" CHIP_ERROR_FORMAT, err.Format());
            }
        });
    }
}

CHIP_ERROR OccupancySensorRFS::Init()
{
    if (mInitialized) {
        LOG_INF("RF Sensing occupancy sensor already initialized");
        return CHIP_NO_ERROR;
    }
    
    LOG_INF("Initializing RF Sensing occupancy sensor");

    // Initialize timers for deferred processing
    k_timer_init(&mModeIndicatorTimer, ModeIndicatorTimerHandler, nullptr);
    
    // Indicate initial mode via LED
    UpdateModeIndicatorLED();

    // Initialize Matter OccupancySensing cluster instance with RF Sensing feature
    CHIP_ERROR err = InitializeClusterInstance(BitMask<OccupancySensing::Feature, uint32_t>(OccupancySensing::Feature::kRFSensing));
    if (err != CHIP_NO_ERROR) {
        return err;
    }

    // Initialize Channel Sounding
    int ret = channel_sounding_init(OccupancySensorRFS::RfsEventHandler);
    if (ret) {
        LOG_ERR("Channel Sounding initialization failed (err %d)", ret);
    }

    mInitialized = true;
    LOG_INF("RF Sensing occupancy sensor initialized successfully");

    return CHIP_NO_ERROR;
}

void OccupancySensorRFS::HandleButtonEvent(bool button_pressed)
{
    static bool button_handled = false;
    
    if (button_pressed && !button_handled) {
        // Button press - toggle mode
        LOG_INF("Button 1 pressed - toggling RFS mode");
        if (channel_sounding_is_preemptive_mode() == true) {
            channel_sounding_set_preemptive_mode(false);
        } else {
            channel_sounding_set_preemptive_mode(true);
        }
        button_handled = true;
        UpdateModeIndicatorLED();
    } else if (!button_pressed) {
        // Button released - reset handler flag
        button_handled = false;
    }
}

void OccupancySensorRFS::UpdateModeIndicatorLED()
{
    if (channel_sounding_is_preemptive_mode()) {
        // Preemptive mode - start blinking timer - LED will blink every 1 second
        dk_set_led_off(DK_LED2);
        k_timer_start(&mModeIndicatorTimer, K_MSEC(1000), K_MSEC(1000));
        LOG_INF("LED2: Preemptive mode - blinking every 1s");
    } else {
        // Non-preemptive mode - stop blinking timer and set LED2 solid on
        k_timer_stop(&mModeIndicatorTimer);
        dk_set_led_on(DK_LED2);
        LOG_INF("LED2: Non Preemptive mode - solid ON");
    }
}

void OccupancySensorRFS::ModeIndicatorTimerHandler(k_timer *timer)
{
    ARG_UNUSED(timer);
    
    // Get the sensor instance (singleton)
    OccupancySensorRFS *sensor = &OccupancySensorRFS::Instance();
    
    sensor->mLedBlinkState = !sensor->mLedBlinkState;
    if (sensor->mLedBlinkState) {
        dk_set_led_on(DK_LED2);
    } else {
        dk_set_led_off(DK_LED2);
    }
}

bool OccupancySensorRFS::IsOccupied(chip::EndpointId endpointId) const
{
    if (endpointId != kInvalidEndpointId) {
        // Check specific endpoint
        if (!IsValidEndpoint(endpointId)) {
            LOG_ERR("Invalid endpoint ID: %u", endpointId);
            return false;
        }
        chip::BitMask<Clusters::OccupancySensing::OccupancyBitmap> currentOccupancy;
        Protocols::InteractionModel::Status status = OccupancySensing::Attributes::Occupancy::Get(endpointId, &currentOccupancy);
        VerifyOrDie(status == Protocols::InteractionModel::Status::Success);
        return currentOccupancy.Has(Clusters::OccupancySensing::OccupancyBitmap::kOccupied);
    } else {
        // Check all RF Sensing endpoints
        for (chip::EndpointId ep = kRfsFirstEndpoint; ep <= kRfsLastEndpoint; ++ep) {
            chip::BitMask<Clusters::OccupancySensing::OccupancyBitmap> currentOccupancy;
            Protocols::InteractionModel::Status status = OccupancySensing::Attributes::Occupancy::Get(ep, &currentOccupancy);
            VerifyOrDie(status == Protocols::InteractionModel::Status::Success);
            if (currentOccupancy.Has(Clusters::OccupancySensing::OccupancyBitmap::kOccupied)) {
                return true;
            }
        }
        return false;
    }
}
#if 0
CHIP_ERROR OccupancySensorRFS::SetHoldTime(uint16_t holdTimeSec)
{
    // Set hold time for all RF Sensing endpoints
    for (chip::EndpointId ep = kRfsFirstEndpoint; ep <= kRfsLastEndpoint; ++ep) {
        if(*OccupancySensing::GetHoldTimeForEndpoint(ep) == holdTimeSec) {
            continue; // already set
        }
        CHIP_ERROR err = OccupancySensing::SetHoldTime(ep, holdTimeSec);
        if (err != CHIP_NO_ERROR) {
            LOG_ERR("Failed to set OccupancySensorType for endpoint %u: %" CHIP_ERROR_FORMAT, ep, err.Format());
            return err;
        }
        if (IsOccupied(ep)) {
            // Restart occupancy present timer with new hold time
            Nrf::PostTask([ep] {
                CHIP_ERROR err = OccupancySensorRFS::Instance().SetOccupancyState(true, ep);
                if (err != CHIP_NO_ERROR) {
                    LOG_ERR("Failed to set RF Sensing occupancy state: %" CHIP_ERROR_FORMAT, err.Format());
                }
            });
        }
    }
    LOG_INF("Set RFSHoldTime to %u seconds for all RF Sensing endpoints", holdTimeSec);

    return CHIP_NO_ERROR;
}
#endif
```

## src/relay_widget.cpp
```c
/*
 * Copyright (c) 2021 Nordic Semiconductor ASA
 *
 * SPDX-License-Identifier: LicenseRef-Nordic-5-Clause
 */

#include "relay_widget.h"
#include <zephyr/device.h>
#include <zephyr/drivers/gpio.h>

static const struct device *relay_dev;

#define RELAY_PORT gpio0
#define RELAY_GPIO 1

int RelayWidget::Init(void)
{
    int err;

	mGPIONum = RELAY_GPIO;
	relay_dev = DEVICE_DT_GET(DT_NODELABEL(RELAY_PORT));
	if (!device_is_ready(relay_dev)) {
		printk("GPIO controller not ready");
		return -EINVAL;
	}
	err = gpio_pin_configure(relay_dev, mGPIONum, GPIO_OUTPUT); 
	if (err != 0) {
		printk("Failed to configure pin %d\n", mGPIONum);
		return -EINVAL;
	}

	Set(false);
    return 0;
}

void RelayWidget::Invert()
{
	Set(!mState);
}

void RelayWidget::Set(bool state)
{
	DoSet(state);
}

void RelayWidget::DoSet(bool state)
{
	mState = state;
	gpio_pin_set(relay_dev, mGPIONum, mState);
}
```

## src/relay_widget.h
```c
/*
 * Copyright (c) 2023 Nordic Semiconductor ASA
 *
 * SPDX-License-Identifier: LicenseRef-Nordic-5-Clause
 */

#pragma once

#include <cstdint>
#include <zephyr/kernel.h>

class RelayWidget {
public:
	int Init();
	void Set(bool state);
	void Invert();

private:
	uint32_t mGPIONum;
	bool mState;
	void DoSet(bool state);
};
```
